# N32MC47x_DP47x register map
Vendor: Nsingtech Ltd.; File version: 1.0
Registers are 32-bit, read-write, reset 0x0 unless marked. A register's access mark holds for its fields unless they carry their own. Offsets are from the block's base; [hi:lo] are bit positions; {n}, {i} and the like mark numbered series.

## AFIO — Alternate function I/O
Base 0x40010800
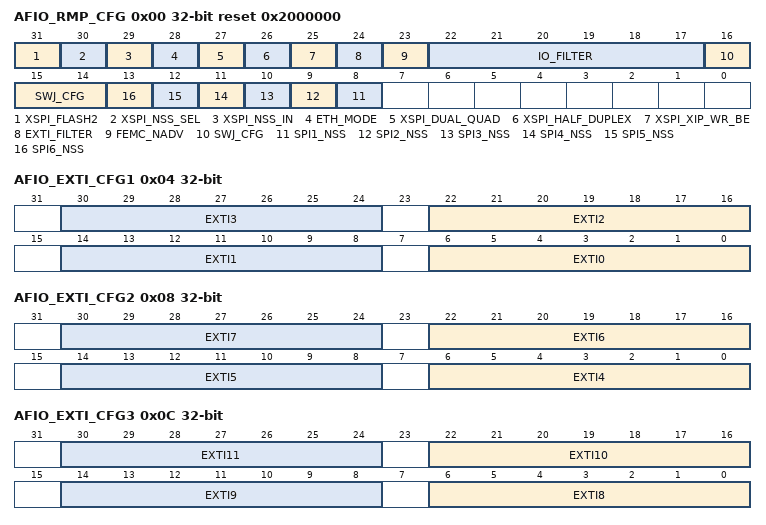
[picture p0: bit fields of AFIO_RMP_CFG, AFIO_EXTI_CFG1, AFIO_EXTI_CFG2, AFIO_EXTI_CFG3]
0x00 AFIO_RMP_CFG reset 0x2000000 — AFIO remapping configuration register
  [31] XSPI_FLASH2 — FLASH2 enable bit in XSPI Dual-Quad mode
  [30] XSPI_NSS_SEL — Select the valid NSS pin when NSS input is enabled in master mode
  [29] XSPI_NSS_IN — NSS input enable bit in master mode,it is used for multi-master test
  [28] ETH_MODE — ETH PHY interface mode configuration bit
  [27] XSPI_DUAL_QUAD — Dual-Quad mode enable bit
  [26] XSPI_HALF_DUPLEX — Half-Duplex mode enable bit
  [25] XSPI_XIP_WR_BE — Big endian enable bit in XIP mode
  [24] EXTI_FILTER — EXTI analog filter configuration bit
  [23] FEMC_NADV — FEMC NADV signal control bit
  [22:17] IO_FILTER — IO digital filter configuration bits
  [16:14] SWJ_CFG — Serial wire JTAG configuration bits
  [n+7] SPI{n}_NSS (n=1..6) — NSS state configuration bit for SPI{n} when idle
0x04 AFIO_EXTI_CFG1 — AFIO external interrupt configuration register 1
  [8n+6:8n] EXTI{n} (n=0..3)
0x08 AFIO_EXTI_CFG2 — AFIO external interrupt configuration register 2
  [8n-26:8n-32] EXTI{n} (n=4..7)
0x0C AFIO_EXTI_CFG3 — AFIO external interrupt configuration register 3
  [8n-58:8n-64] EXTI{n} (n=8..11)
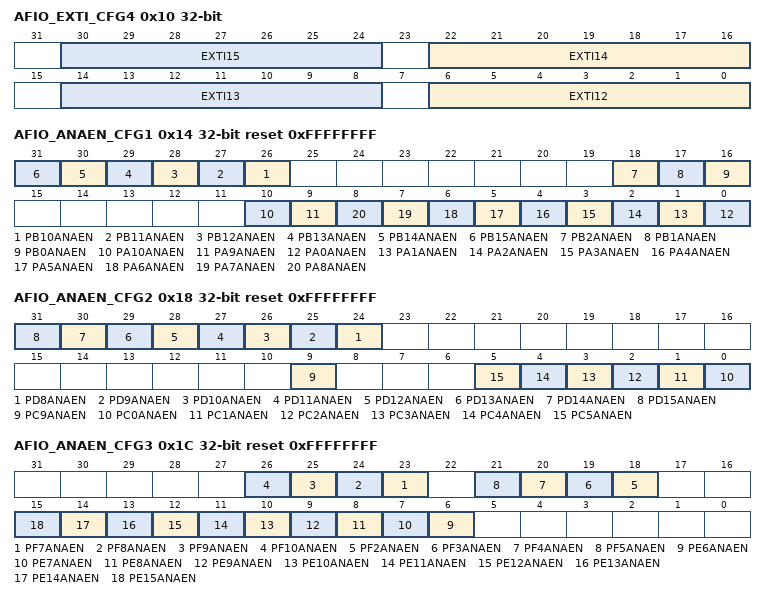
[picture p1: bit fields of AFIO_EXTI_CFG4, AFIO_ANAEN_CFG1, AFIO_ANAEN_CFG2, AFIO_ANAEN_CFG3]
0x10 AFIO_EXTI_CFG4 — AFIO external interrupt configuration register 4
  [8n-90:8n-96] EXTI{n} (n=12..15)
0x14 AFIO_ANAEN_CFG1 reset 0xFFFFFFFF — AFIO IO port analog signal channel configuration register 1
  [n+16] PB{n}ANAEN (n=10..15)
  [18] PB2ANAEN
  [17] PB1ANAEN
  [16] PB0ANAEN
  [10] PA10ANAEN — PA12ANAEN
  [9] PA9ANAEN — PA11ANAEN
  [n] PA{n}ANAEN (n=0..8)
0x18 AFIO_ANAEN_CFG2 reset 0xFFFFFFFF — AFIO IO port analog signal channel configuration register 2
  [n+16] PD{n}ANAEN (n=8..15), [9] PC9ANAEN, [n] PC{n}ANAEN (n=0..5)
0x1C AFIO_ANAEN_CFG3 reset 0xFFFFFFFF — AFIO IO port analog signal channel configuration register 3
  [n+16] PF{n}ANAEN (n=7..10), [n+16] PF{n}ANAEN (n=2..5), [n] PE{n}ANAEN (n=6..15)
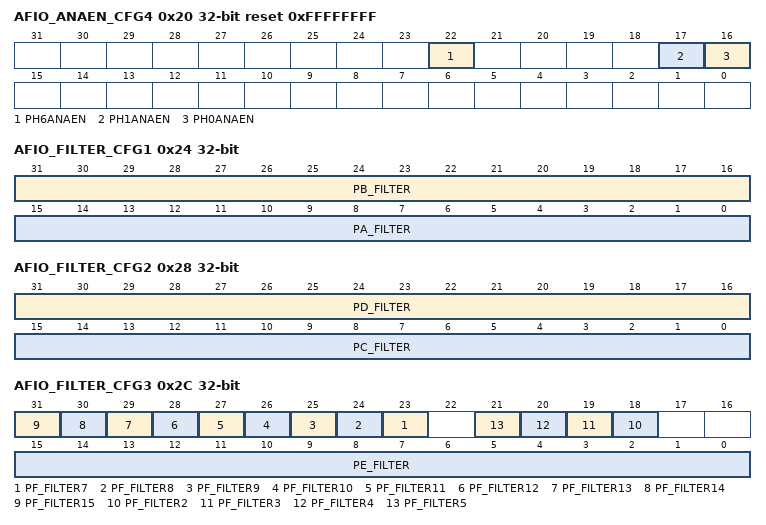
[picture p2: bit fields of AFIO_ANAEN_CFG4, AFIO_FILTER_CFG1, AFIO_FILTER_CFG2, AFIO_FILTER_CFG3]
0x20 AFIO_ANAEN_CFG4 reset 0xFFFFFFFF — AFIO IO port analog signal channel configuration register 4
  [22] PH6ANAEN, [17] PH1ANAEN, [16] PH0ANAEN
0x24 AFIO_FILTER_CFG1 — AFIO IO port digtal filter configuration register 1
  [31:16] PB_FILTER, [15:0] PA_FILTER
0x28 AFIO_FILTER_CFG2 — AFIO IO port digtal filter configuration register 2
  [31:16] PD_FILTER, [15:0] PC_FILTER
0x2C AFIO_FILTER_CFG3 — AFIO IO port digtal filter configuration register 3
  [n+16] PF_FILTER{n} (n=7..15), [n+16] PF_FILTER{n} (n=2..5), [15:0] PE_FILTER
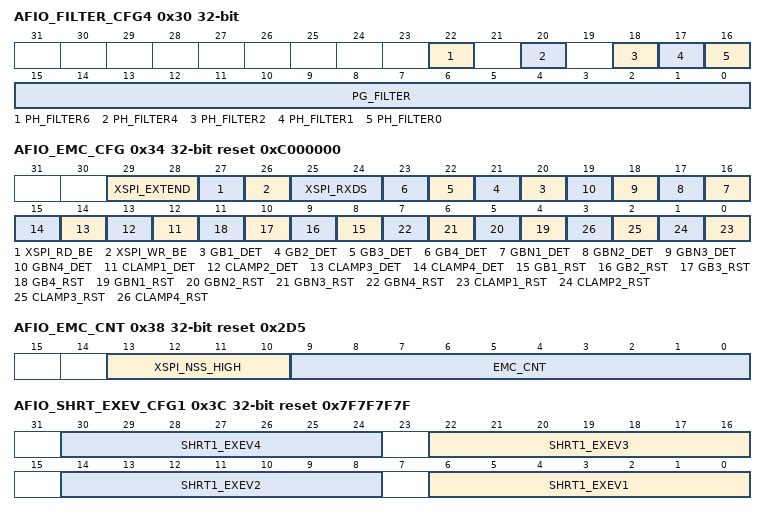
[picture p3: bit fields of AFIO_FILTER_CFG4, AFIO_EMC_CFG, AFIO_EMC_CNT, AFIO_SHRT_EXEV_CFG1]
0x30 AFIO_FILTER_CFG4 — AFIO IO port digtal filter configuration register 4
  [22] PH_FILTER6, [20] PH_FILTER4, [18] PH_FILTER2, [17] PH_FILTER1, [16] PH_FILTER0, [15:0] PG_FILTER
0x34 AFIO_EMC_CFG reset 0xC000000 — AFIO EMC configuration register
  [29:28] XSPI_EXTEND — XSPI NSS setup time and hold time extension configuration bits
  [27] XSPI_RD_BE — Big endian enable bit for XSPI normal read operation (not XIP)
  [26] XSPI_WR_BE — Big endian enable bit for XSPI normal write operation (not XIP)
  [25:24] XSPI_RXDS — The data sample delay time for XSPI RXDS signal
  [n+19] GB{n}_DET (n=1..4)
  [n+15] GBN{n}_DET (n=1..4)
  [n+11] CLAMP{n}_DET (n=1..4)
  [n+7] GB{n}_RST (n=1..4)
  [n+3] GBN{n}_RST (n=1..4)
  [n-1] CLAMP{n}_RST (n=1..4)
0x38 AFIO_EMC_CNT reset 0x2D5 — AFIO EMC counter register
  [13:10] XSPI_NSS_HIGH — XSPI NSS high level time(idle) cofiguration bits
  [9:0] EMC_CNT — EMC error counter
0x3C AFIO_SHRT_EXEV_CFG1 reset 0x7F7F7F7F — AFIO SHRTIM1 EXEV configuration register 1
  [8n-2:8n-8] SHRT1_EXEV{n} (n=1..4) — SHRTIM1 EXEV{n} source selectiong
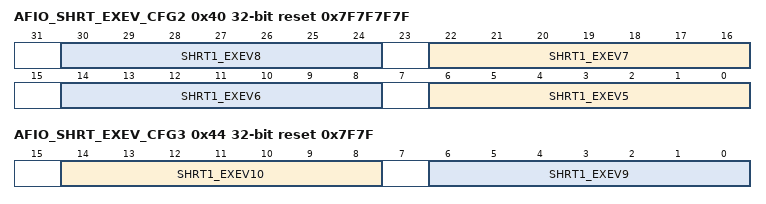
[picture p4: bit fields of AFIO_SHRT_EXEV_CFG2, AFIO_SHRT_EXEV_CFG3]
0x40 AFIO_SHRT_EXEV_CFG2 reset 0x7F7F7F7F — AFIO SHRTIM1 EXEV configuration register 2
  [8n-34:8n-40] SHRT1_EXEV{n} (n=5..8) — SHRTIM1 EXEV{n} source selectiong
0x44 AFIO_SHRT_EXEV_CFG3 reset 0x7F7F — AFIO SHRTIM1 EXEV configuration register 3
  [14:8] SHRT1_EXEV10 — SHRTIM1 EXEV10 source selectiong
  [6:0] SHRT1_EXEV9 — SHRTIM1 EXEV9 source selectiong
